# DW_ahb_dmac: IP-XACT component
VLNV Synopsys:DesignWareLibrary:DW_ahb_dmac:2.14a

## Parameters
USE_FOUNDATION = 1 — USE_FOUNDATION. The component code utilizes DesignWare Foundation parts for optimal Synthesis QoR. Customers with only a DesignWare license MUST use Foundation parts. Customers with only a Source license, CANNOT use Foundation parts. Customers with both Source and DesignWare licenses have the option of using Foundation parts.
DMAH_NUM_MASTER_INT = 1 — DMAH_NUM_MASTER_INT. Number of AHB master interfaces. A channel's source and destination device can be programmed to be on any of the configured AHB layer's attached to the AHB Master interfaces. This setting determines if a master interface's signal set is present on the I/O or not. AHB master 1 interface signals are always present.
DMAH_NUM_CHANNELS = 1 — DMAH_NUM_CHANNELS. Number Of DMA channels. Each channel is uni-directional and transfers data from the channel's source to the channel's destination. The channel's source and destination AHB layer, system address and handshaking interface are under software control.
DMAH_NUM_HS_INT = 2 — DMAH_NUM_HS_INT. Number of handshaking interfaces. Each channel's source and destination can be assigned a handshaking interface. This is under software control. If 0 is selected then no hardware handshaking interface signals will be present on the I/O.
DMAH_ID_NUM = 0x0 — DMAH_ID_NUM. This 32-bit value is hardwired and read back by a read to the DMA Controller ID Register (DmaldReg).
DMAH_INTR_POL = 0 — DMAH_INTR_POL. Interrupt active polarity for all of the configured interrupt ports. When this box is selected the interrupt polarity for all interrupt pins on the I/O interface is active low. When this box is de-selected the interrupt polarity for all interrupt pins on the I/O interface is active high.
DMAH_INTR_IO = 2 — DMAH_INTR_IO. Selects which interrupt related pins appear as outputs of the design. all - Contents of all five Interrupts Status Registers appear as output pins on int(_n) output bus. 5 * DMAH_NUM_CHANNELS bits wide. type - All internal interrupts are combined by type and appear on int_flag(_n) output bus. 5 bit bus. bit[4] = Error interrupt bit[3] = Destination transaction complete interrupt bit[2] = Source transaction complete interrupt bit[1] = Block complete interrupt bit[0] = Transfer complete interrupt Bitwise OR of all bits of int_flag(_n) bus is also driven onto the int_combined single bit output port. combined - Bitwise OR of all bits of int_flag(_n) bus is driven onto the int_combined(_n) single bit output port.
DMAH_MABRST = 0 — DMAH_MABRST. Selecting this box will allow software to limit the maximum AMBA burst length to a value under software control. This is a global parameter for all of the configured master interfaces. If this box is not selected then software cannot limit the the maximum AMBA burst length. The maximum possible AMBA burst length in this case will be determined by the depth of the channel FIFO's as the DMA controller may try to fill/empty the channel FIFO in a single AMBA burst. De-selecting this box will allow for some logic optimization.
DMAH_INCR_BURSTS = 1 — DMAH_INCR_BURSTS. When this option is selected then all bursts will be undefined length bursts. When this option is not selected then all bursts will be defined length bursts.
DMAH_RETURN_ERR_RESP = 1 — DMAH_RETURN_ERR_RESP. Selecting this box will allow the slave interface to return an error response on the hresp bus when an illegal access is attempted over the AHB slave interface. An illegal access is any of the following: 1. An AMBA transfer of hsize > 64 bits is attempted. 2. hsel is asserted but the address does not decode to a valid address. 3. A write to the sar, dar, ctl, llp, sstat, dstat, sstatar and dstatar registers is attempted when the channel is enabled. 4. A read from the interrupt clear registers, ClearTfr, ClearBlock, ClearSrcTran, ClearDstTran, ClearErr is attempted. 5. A write to the Interrupt status registers, StatusTfr, StatusBlock, StatusSrcTran, StatusDstTran, StatusErr is attempted. 6. A write to the StatusInt register is attempted. 7. A write to either the DmaIdReg or DmaVersionId registers is attempted. De-selecting this box will result in an O.K. response been returned on the hresp bus for all off the illegal access's listed above. Note in both cases an illegal read will read back 0 and an illegal write will be ignored.
DMAH_ADD_ENCODED_PARAMS = 0x1 — Adding the encoded parameters gives firmware an easy and quick way of identifying the DesignWare component within an I/O memory map. Some critical design-time options determine how a driver should interact with the peripheral. There is a minimal area overhead when you include these parameters. Additionally, this option allows a self-configurable single driver to be developed for each component.
DMAH_STATIC_ENDIAN_SELECT = 1 — DMAH_STATIC_ENDIAN_SELECT. The endianness of the DW_ahb_dmac can be configured statically through coreConsultant or dynamically via pins on the I/O - For the static case there is a single coreConsultant parameter that controls the endianness of all AHB master interfaces and the AHB slave interface. For the dynamic case there is an individual pin for each of the AHB master interfaces and one for the AHB slave interface.
DMAH_BIG_ENDIAN = 0 — DMAH_BIG_ENDIAN. The AHB master interfaces and the AHB slave interface can be configured to exist in either a big or little endian system. All master interfaces and the AHB slave interface have the same endianness. If this box is selected then all configured AHB master interfaces and the AHB slave interface will be configured to be big endian. If this box is de-selected then all configured AHB master interfaces and the AHB slave interface will be configured to be little endian.
DMAH_S_HDATA_WIDTH = 32 — DMAH_S_HDATA_WIDTH. Slave interface data bus width.
DMAH_M{n}_AHB_LITE = 0 (n=1..4) — DMAH_M{n}_AHB_LITE. Select this box if master interface {n} is the only master on this AMBA layer. If this is the case then this is an AMBA-Lite layer. De-select this box if there is more than one master on this AMBA layer.
DMAH_M{n}_HDATA_WIDTH = 32 (n=1..4) — DMAH_M{n}_HDATA_WIDTH. Master {n} interface data bus width.
DMAH_CH{n}_FIFO_DEPTH = 16 (n=0..7) — DMAH_CH{n}_FIFO_DEPTH. Channel {n} FIFO depth in bytes.
DMAH_CH{n}_MAX_MULT_SIZE = 8 (n=0..7) — DMAH_CH{n}_MAX_MULT_SIZE. Maximum value of burst transaction size that can be programmed for channel {n}. Programming either of the ctl{n}.src_msize or ctl{n}.dest_msize registers to a value greater than this cC constant will result in erroneous behavior. Limiting this value with a cC constant will allow for some logic optimization of the implementation.
DMAH_CH{n}_MAX_BLK_SIZE = 31 (n=0..7) — DMAH_CH{n}_MAX_BLK_SIZE. The behavior of this cC constant is dependent on the assignment of the flow control peripheral. 1. DMA is flow controller Maximum block length, in multiples off source transfer width, that can be programmed for channel {n}. A programmed value greater than this will result in erroneous behavior. 2. Either of the source or destination peripherals assigned as flow controller In this case the blocks can be greater than DMAH_CH{n}_MAX_BLK_SIZE but the logic that keeps track of the length of the block saturates at DMAH_CH{n}_MAX_BLK_SIZE. This will not result in erroneous behavior but a readback of the block size will be incorrect when blocks exceed the saturated value. This parameter is also used to limit channel {n}'s scatter and gather count registers to hold a maximum value of DMAH_CH{n}_MAX_BLK_SIZE. Limiting this value with a cC constant will allow for some logic optimization of the implementation.
DMAH_CH{n}_FC = 0 (n=0..7) — DMAH_CH{n}_FC. Hardcode the flow control peripheral for channel {n}. Hardcoding the flow control peripheral will allow for some logic optimization of the implementation. DMA_FC : Hardcodes the DMA as the block flow controlling device SRC_FC_ONLY : Hardcodes the source peripheral as the block flow controlling device DST_FC_ONLY : Hardcodes the destination peripheral as the block flow controlling device ANY_FC : Does not hardcode the block flow control device and allows software to select the block flow control device.
DMAH_CH{n}_LOCK_EN = 0 (n=0..7) — DMAH_CH{n}_LOCK_EN. Include or exclude logic to enable channel or bus level locking on channel {n}. When enabled, then software can program the DMA controller to assert hlock over the DMA transfer, DMA block transfer or DMA transaction. When enabled, then software can also program the DMA controller to lock the arbitration for the master bus interface unit over the DMA transfer, DMA block transfer or DMA transaction. De-selecting this option allows for some logic optimization of the implementation.
DMAH_CH{n}_SMS = 0 (n=0..7) — DMAH_CH{n}_SMS. Hardcode the Master interface attached to the source of channel {n}. If this is not hardcoded then software can program the source of channel {n} to be attached to any of the configured layers. Hardcoding this value will allow for some logic optimization of the implementation.
DMAH_CH{n}_DMS = 0 (n=0..7) — DMAH_CH{n}_DMS. Hardcode the Master interface attached to the destination of channel {n}. If this is not hardcoded then software can program the destination of channel {n} to be attached to any of the configured layers. Hardcoding this value will allow for some logic optimization of the implementation.
DMAH_CH{n}_STW = 32 (n=0..7) — DMAH_CH{n}_STW. Hardcode the source transfer width for transfers from the source of channel {n}. If this is not hardcoded then software can program the source transfer width for channel {n}. Hardcoding this value will allow for some logic optimization of the implementation.
DMAH_CH{n}_DTW = 32 (n=0..7) — DMAH_CH{n}_DTW. Hardcode the destination transfer width for transfers from the destination of channel {n}. If this is not hardcoded then software can program the destination transfer width for channel {n}. Hardcoding this value will allow for some logic optimization of the implementation.
DMAH_CH0_SRC_NON_OK = 1 — DMAH_CH0_SRC_NON_OK. Should be selected if the source peripheral attached to channel 0 can return a non-ok response on hresp. i.e. either split, retry or error response. If this box is de-selected then hardware assumes that only o.k. responses will be returned from the source of channel 0. De-selecting this box will allow for some logic optimization of the implementation.
DMAH_CH0_DST_NON_OK = 1 — DMAH_CH0_DST_NON_OK. Should be selected if the destination peripheral attached to channel 0 can return a non-ok response on hresp. i.e. either split, retry or error response. If this box is de-selected then hardware assumes that only o.k. responses will be returned from the destination of channel 0. De-selecting this box will allow for some logic optimization of the implementation.
DMAH_CH{n}_MULTI_BLK_EN = 0 (n=0..7) — DMAH_CH{n}_MULTI_BLK_EN. Include or exclude logic to enable multi-block DMA transfers on channel {n}. If this option is de-selected then hardware will hardwire channel {n} to do single block transfers only. De-selecting this box will allow for some logic optimization of the implementation.
DMAH_CH{n}_HC_LLP = 1 (n=0..7) — DMAH_CH{n}_HC_LLP. If the Linked List Pointer ( LLP ) register is hardcoded to 0 then this will disable the following features on channel {n}: 1. Multi-block DMA transfers using block chaining 2. Source and destination status fetch 3. Control and source/destination status writeback Multi-block DMA transfers may still be enabled on channel {n} through auto-reloading of channel registers. Selecting this box will allow for some logic optimization of the implementation.
DMAH_CH{n}_MULTI_BLK_TYPE = 0 (n=0..7) — DMAH_CH{n}_MULTI_BLK_TYPE. This parameter allows the user to hardcode the type of multi-block transfers that the DW_ahb_dmac can perform. This will result in some logic optimization of the implementation. NO_HARDCODE : Allow all types of multi-block support CONT_RELOAD : Allow only multi-block transfers where SAR{n} is contigious, DAR{n} and CTL{n} are reloaded from their initial values RELOAD_CONT : Allow only multi-block transfers where SAR{n} and CTL{n} are reloaded from their initial values, DAR{n} is contigious RELOAD_RELOAD : Allow only multi-block transfers where SAR{n},DAR{n} and CTL{n} are reloaded from their initial values CONT_LLP : Allow only multi-block transfers where SAR{n} is contigious, DAR{n},CTL{n} and LLP{n} are loaded from the next Linked List Item RELOAD_LLP : Allow only multi-block transfers where SAR{n} is reloaded from it's initial value, DAR{n},CTL{n} and LLP{n} are loaded from the next Linked List Item LLP_CONT : Allow only multi-block transfers where SAR{n},CTL{n} and LLP{n} are loaded from the next Linked List Item, DAR{n} is contigious LLP_RELOAD : Allow only multi-block transfers where SAR{n},CTL{n} and LLP{n} are loaded from the next Linked List Item, DAR{n} is reloaded from it's initial values LLP_LLP : Allow only multi-block transfers where SAR{n},DAR{n},CTL{n} and LLP{n} are loaded from the next
DMAH_CH{n}_STAT_SRC = 0 (n=0..7) — DMAH_CH{n}_STAT_SRC. Include or exclude logic to fetch a status register from the source peripheral of channel {n} and write this status information to system memory at the end of each block transfer. The location from where the source status register is fetched from is under software control as is the writeback location. De-selecting this box will allow for some logic optimization of the implementation.
DMAH_CH{n}_STAT_DST = 0 (n=0..3) — DMAH_CH{n}_STAT_DST. Include or exclude logic to fetch a status register from the destination peripheral of channel {n} and write this status information to system memory at the end of each block transfer. The location from where the destination status register is fetched from is under software control as is the writeback location. De-selecting this box will allow for some logic optimization of the implementation.
DMAH_CH{n}_LMS = 0 (n=0..7) — DMAH_CH{n}_LMS. Hardcode the Master interface attached to the Linked List Pointer (LLP) peripheral of channel {n}. If this is not hardcoded then software can program the LLP peripheral of channel {n} to be attached to any of the configured layers. Hardcoding this value will allow for some logic optimization of the implementation.
DMAH_CH0_LLP_NON_OK = 0 — DMAH_CH0_LLP_NON_OK. Should be selected if the linked list pointer (LLP) peripheral attached to channel 0 can return a non-ok response on hresp. i.e. either split, retry or error response. If de-selected then hardware assumes that only o.k. responses will be returned from the LLP peripheral of channel 0. De-selecting this box will allow for some logic optimization of the implementation.
DMAH_CH{n}_SRC_GAT_EN = 0 (n=0..7) — DMAH_CH{n}_SRC_GAT_EN. Include or exclude logic to enable the 'gather' feature on channel {n}. De-selecting this box will allow for some logic optimization of the implementation.
DMAH_CH{n}_DST_SCA_EN = 0 (n=0..7) — DMAH_CH{n}_DST_SCA_EN. Include or exclude logic to enable the 'scatter' feature on channel {n}. De-selecting this box will allow for some logic optimization of the implementation.
DMAH_CH{n}_CTL_WB_EN = 0 (n=0..7) — DMAH_CH{n}_CTL_WB_EN. Include or exclude logic to enable writeback of the control register at the end of every block transfer. De-selecting this box will allow for some logic optimization of the implementation.
DMAH_CH{n}_SRC_NON_OK = 1 (n=1..7) — DMAH_CH{n}_SRC_NON_OK. Should be selected if the source peripheral attached to channel {n} can return a non-ok response on hresp. i.e. either split/retry or error response. If this box is de-selected then hardware assumes that only o.k. responses will be returned from the source of channel {n}. De-selecting this box will allow for some logic optimization of the implementation.
DMAH_CH{n}_DST_NON_OK = 1 (n=1..7) — DMAH_CH{n}_DST_NON_OK. Should be selected if the destination peripheral attached to channel {n} can return a non-ok response on hresp. i.e. either split/retry or error response. If this box is de-selected then hardware assumes that only o.k. responses will be returned from the destination of channel {n}. De-selecting this box will allow for some logic optimization of the implementation.
DMAH_CH1_LLP_NON_OK = 0 — DMAH_CH1_LLP_NON_OK. Should be selected to true if the linked list pointer (LLP) peripheral attached to channel 1 can return a non-ok response on hresp. i.e. either split, retry or error response. If de-selected then hardware assumes that only o.k. responses will be returned from the LLP peripheral of channel 1. De-selecting this box will allow for some logic optimization of the implementation.
DMAH_CH2_LLP_NON_OK = 0 — DMAH_CH2_LLP_NON_OK. Should be selected to true if the linked list pointer (LLP) peripheral attached to channel 2 can return a non-ok response on hresp. i.e. either split, retry or error response. If de-selected then hardware assumes that only o.k. responses will be returned from the LLP peripheral of channel 2. De-selecting this box will allow for some logic optimization of the implementation.
DMAH_CH3_LLP_NON_OK = 0 — DMAH_CH3_LLP_NON_OK. Should be set to true if the linked list pointer (LLP) peripheral attached to channel 3 can return a non-ok response on hresp. i.e. either split, retry or error response. If de-selected then hardware assumes that only o.k. responses will be returned from the LLP peripheral of channel 3. De-selecting this box will allow for some logic optimization of the implementation.
DMAH_CH4_STAT_DST = 0 — DMAH_CH4_STAT_DST. Include or exclude logic to fetch a status register from the destination peripheral of channel 0 and write this status information to system memory at the end of each block transfer. The location from where the destination status register is fetched from is under software control as is the writeback location. De-selecting this box will allow for some logic optimization of the implementation.
DMAH_CH{n}_LLP_NON_OK = 0 (n=4..7) — DMAH_CH{n}_LLP_NON_OK. Should be selected to true if the linked list pointer (LLP) peripheral attached to channel {n} can return a non-ok response on hresp. i.e. either split, retry or error response. If de-selected then hardware assumes that only o.k. responses will be returned from the LLP peripheral of channel {n}. De-selecting this box will allow for some logic optimization of the implementation.
DMAH_CH{n}_STAT_DST = 0 (n=5..7) — DMAH_CH{n}_STAT_DST. Include or exclude logic to fetch a status register from the destination peripheral of channel {n} and write this status information to system memory at the end of each block transfer. The location from where the destination status register is fetched from is under software control as is the writeback location. De-selecting this box will allow for some logic optimization of the implementation.

## Bus interfaces (logical=physical port)
AHB_Master1: master amba.com:busdef.amba.amba2:ahb:r1p0 — Bus Master side of the AHB. On this interface the 'consumer's are AHB masters, and the 'provider' is the central bus IP.
  hsize=hsize1, hresp=hresp1, hgrant=hgrant1, hburst=hburst1, hwrite=hwrite1, hwdata=hwdata1, htrans=htrans1, hbusreq=hbusreq1, hrdata=hrdata1, hready=hready1, haddr=haddr1, hprot=hprot1, hlock=hlock1
AHB_Slave: slave amba.com:busdef.amba.amba2:ahb:r1p0 — Bus Slave side of the AHB. On this interface the 'consumer's are AHB slaves, and the 'provider' is the central bus IP.
  hsel=hsel, hready_resp=hready_resp, hrdata=hrdata, htrans=htrans, hsize=hsize, hready=hready, hwrite=hwrite, haddr=haddr, hresp=hresp, hwdata=hwdata
HCLK: system amba.com:busdef.amba.amba2:ahb:r1p0 — Clock signal for AHB masters and slaves. Connections typically go from an exported interface to each AHB master/slave and the bus itself.
  hclk=hclk
HRESETn: system amba.com:busdef.amba.amba2:ahb:r1p0 — Reset signal for AHB masters and slaves. Connections typically go from an exported interface to each AHB master/slave and the bus itself.
  hresetn=hresetn
int_combined: mirroredSlave Synopsys:DesignWareLibrary:DW-SoC::Source-Interrupt:2.0 — Source interrupt signals connected to an interrupt controller.
  irq=int_combined_n

## Ports
in dma_last[1:0]
in dma_req[1:0]
in dma_single[1:0]
in haddr[31:0]
in hclk
in hgrant1
in hrdata1[31:0]
in hready
in hready1
in hresetn
in hresp1[1:0]
in hsel
in hsize[2:0]
in htrans[1:0]
in hwdata[31:0]
in hwrite
out debug_ch_enable[0:0]
out debug_dma_ctl_en
out debug_dma_data_req[1:0]
out debug_dum_req_dst_region[0:0]
out debug_dum_req_src_region[0:0]
out debug_en_dst_hs_sgl[0:0]
out debug_en_src_hs_sgl[0:0]
out debug_fifo_empty[0:0]
out debug_fifo_half_full[0:0]
out debug_fifo_ready_dst[0:0]
out debug_fifo_ready_src[0:0]
out debug_grant_index_m1[0:0]
out debug_granted_m1
out debug_length_m_i[4:0]
out debug_mask_lck_ch_m1[1:0]
out debug_rd_int_en[0:0]
out debug_rd_maskblock[0:0]
out debug_rd_maskdsttran[0:0]
out debug_rd_maskerr[0:0]
out debug_rd_masksrctran[0:0]
out debug_rd_masktfr[0:0]
out debug_rd_rawblock[0:0]
out debug_rd_rawdsttran[0:0]
out debug_rd_rawerr[0:0]
out debug_rd_rawsrctran[0:0]
out debug_rd_rawtfr[0:0]
out debug_req_mi1[1:0]
out debug_statusint_dmacore[4:0]
out debug_tfr_req_m1
out dma_ack[1:0]
out dma_finish[1:0]
out haddr1[31:0]
out hburst1[2:0]
out hbusreq1
out hlock1
out hprot1[3:0]
out hrdata[31:0]
out hready_resp
out hresp[1:0]
out hsize1[2:0]
out htrans1[1:0]
out hwdata1[31:0]
out hwrite1
out int_combined_n

## Address spaces and blocks
DMAC.Software_Handshake_Registers: base 0x368, range 0x30, width 64, register
DMAC.Miscellaneous_Registers: base 0x398, range 0x68, width 64, register
DMAC.Interrupt_Registers: base 0x2c0, range 0xa8, width 64, register
DMAC.Channel_0_Registers: base 0x0, range 0x58, width 64, register

## Registers
Registers are 64-bit, read-write, reset 0x0 unless marked. A register's access mark holds for its fields unless they carry their own. Offsets are from the block's base; lines under a group give offsets from that group; [hi:lo] are bit positions; {n}, {i} and the like mark numbered series; 'fields as' and 'values as' point back to an identical list; <NAME> marks a mode.

## DMAC.Software_Handshake_Registers
Base 0x00000368
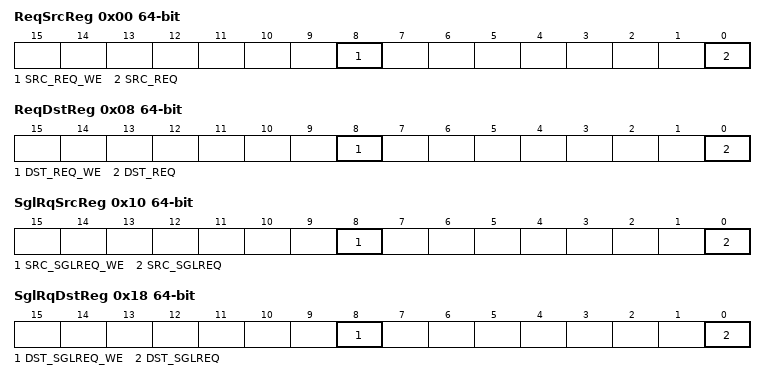
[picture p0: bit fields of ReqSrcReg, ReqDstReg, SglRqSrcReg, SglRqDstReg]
0x00 ReqSrcReg
  [8] SRC_REQ_WE, [0] SRC_REQ
0x08 ReqDstReg
  [8] DST_REQ_WE, [0] DST_REQ
0x10 SglRqSrcReg
  [8] SRC_SGLREQ_WE, [0] SRC_SGLREQ
0x18 SglRqDstReg
  [8] DST_SGLREQ_WE, [0] DST_SGLREQ
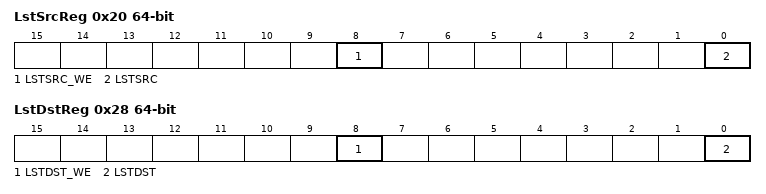
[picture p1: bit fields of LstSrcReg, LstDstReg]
0x20 LstSrcReg
  [8] LSTSRC_WE, [0] LSTSRC
0x28 LstDstReg
  [8] LSTDST_WE, [0] LSTDST

## DMAC.Miscellaneous_Registers
Base 0x00000398
0x00 DmaCfgReg reset not defined
  [0] DMA_EN
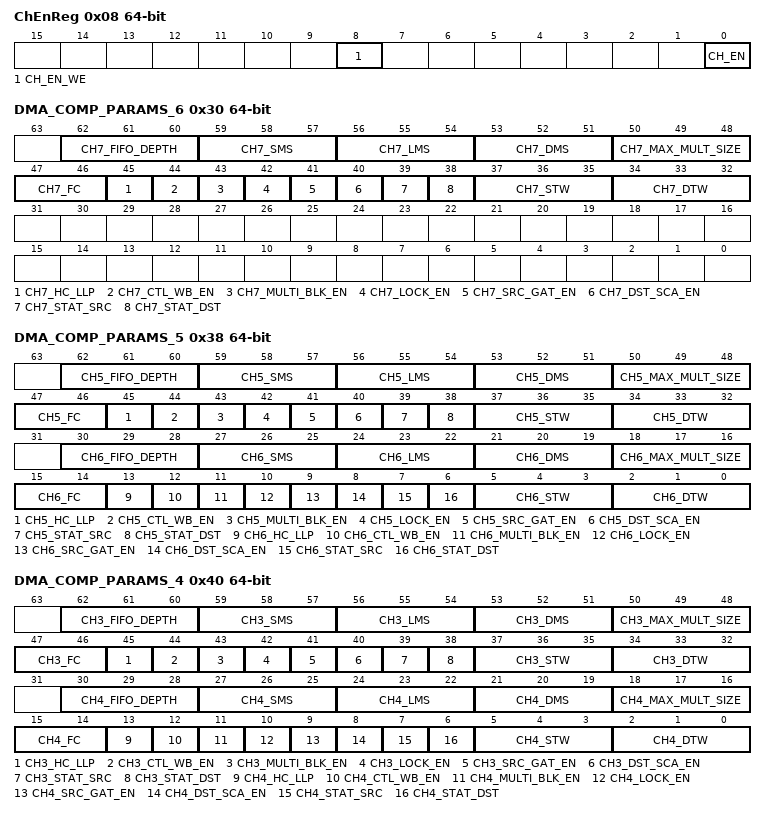
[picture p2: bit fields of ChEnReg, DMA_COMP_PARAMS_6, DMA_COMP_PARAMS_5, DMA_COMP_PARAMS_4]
0x08 ChEnReg reset not defined
  [8] CH_EN_WE, [0] CH_EN
0x10 DmaIdReg ro
  [31:0] DMA_ID
0x18 DmaTestReg reset not defined
  [0] TEST_SLV_IF
0x30 DMA_COMP_PARAMS_6 ro reset not defined
  [62:60] CH7_FIFO_DEPTH, [59:57] CH7_SMS, [56:54] CH7_LMS, [53:51] CH7_DMS, [50:48] CH7_MAX_MULT_SIZE, [47:46] CH7_FC, [45] CH7_HC_LLP, [44] CH7_CTL_WB_EN, [43] CH7_MULTI_BLK_EN, [42] CH7_LOCK_EN, [41] CH7_SRC_GAT_EN, [40] CH7_DST_SCA_EN, [39] CH7_STAT_SRC, [38] CH7_STAT_DST, [37:35] CH7_STW, [34:32] CH7_DTW
0x38 DMA_COMP_PARAMS_5 ro reset not defined
  [62:60] CH5_FIFO_DEPTH, [59:57] CH5_SMS, [56:54] CH5_LMS, [53:51] CH5_DMS, [50:48] CH5_MAX_MULT_SIZE, [47:46] CH5_FC, [45] CH5_HC_LLP, [44] CH5_CTL_WB_EN, [43] CH5_MULTI_BLK_EN, [42] CH5_LOCK_EN, [41] CH5_SRC_GAT_EN, [40] CH5_DST_SCA_EN, [39] CH5_STAT_SRC, [38] CH5_STAT_DST, [37:35] CH5_STW, [34:32] CH5_DTW, [30:28] CH6_FIFO_DEPTH, [27:25] CH6_SMS, [24:22] CH6_LMS, [21:19] CH6_DMS, [18:16] CH6_MAX_MULT_SIZE, [15:14] CH6_FC, [13] CH6_HC_LLP, [12] CH6_CTL_WB_EN, [11] CH6_MULTI_BLK_EN, [10] CH6_LOCK_EN, [9] CH6_SRC_GAT_EN, [8] CH6_DST_SCA_EN, [7] CH6_STAT_SRC, [6] CH6_STAT_DST, [5:3] CH6_STW, [2:0] CH6_DTW
0x40 DMA_COMP_PARAMS_4 ro reset not defined
  [62:60] CH3_FIFO_DEPTH, [59:57] CH3_SMS, [56:54] CH3_LMS, [53:51] CH3_DMS, [50:48] CH3_MAX_MULT_SIZE, [47:46] CH3_FC, [45] CH3_HC_LLP, [44] CH3_CTL_WB_EN, [43] CH3_MULTI_BLK_EN, [42] CH3_LOCK_EN, [41] CH3_SRC_GAT_EN, [40] CH3_DST_SCA_EN, [39] CH3_STAT_SRC, [38] CH3_STAT_DST, [37:35] CH3_STW, [34:32] CH3_DTW, [30:28] CH4_FIFO_DEPTH, [27:25] CH4_SMS, [24:22] CH4_LMS, [21:19] CH4_DMS, [18:16] CH4_MAX_MULT_SIZE, [15:14] CH4_FC, [13] CH4_HC_LLP, [12] CH4_CTL_WB_EN, [11] CH4_MULTI_BLK_EN, [10] CH4_LOCK_EN, [9] CH4_SRC_GAT_EN, [8] CH4_DST_SCA_EN, [7] CH4_STAT_SRC, [6] CH4_STAT_DST, [5:3] CH4_STW, [2:0] CH4_DTW
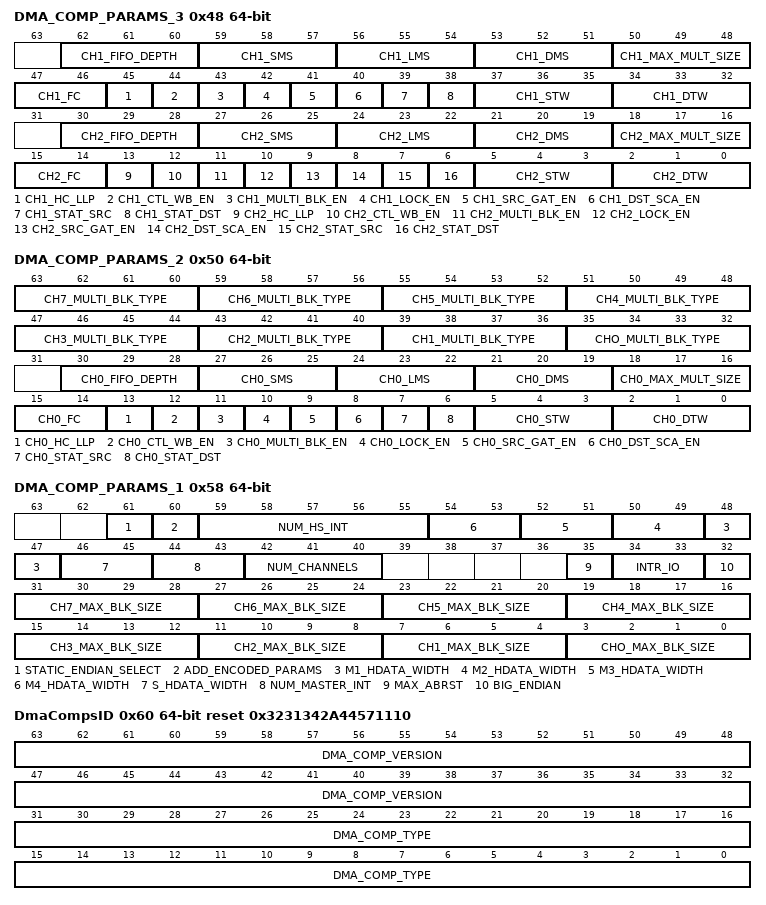
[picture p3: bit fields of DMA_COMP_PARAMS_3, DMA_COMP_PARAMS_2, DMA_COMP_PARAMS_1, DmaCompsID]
0x48 DMA_COMP_PARAMS_3 ro reset not defined
  [62:60] CH1_FIFO_DEPTH, [59:57] CH1_SMS, [56:54] CH1_LMS, [53:51] CH1_DMS, [50:48] CH1_MAX_MULT_SIZE, [47:46] CH1_FC, [45] CH1_HC_LLP, [44] CH1_CTL_WB_EN, [43] CH1_MULTI_BLK_EN, [42] CH1_LOCK_EN, [41] CH1_SRC_GAT_EN, [40] CH1_DST_SCA_EN, [39] CH1_STAT_SRC, [38] CH1_STAT_DST, [37:35] CH1_STW, [34:32] CH1_DTW, [30:28] CH2_FIFO_DEPTH, [27:25] CH2_SMS, [24:22] CH2_LMS, [21:19] CH2_DMS, [18:16] CH2_MAX_MULT_SIZE, [15:14] CH2_FC, [13] CH2_HC_LLP, [12] CH2_CTL_WB_EN, [11] CH2_MULTI_BLK_EN, [10] CH2_LOCK_EN, [9] CH2_SRC_GAT_EN, [8] CH2_DST_SCA_EN, [7] CH2_STAT_SRC, [6] CH2_STAT_DST, [5:3] CH2_STW, [2:0] CH2_DTW
0x50 DMA_COMP_PARAMS_2 ro reset not defined
  [4n+35:4n+32] CH{n}_MULTI_BLK_TYPE (n=1..7), [35:32] CHO_MULTI_BLK_TYPE, [30:28] CH0_FIFO_DEPTH, [27:25] CH0_SMS, [24:22] CH0_LMS, [21:19] CH0_DMS, [18:16] CH0_MAX_MULT_SIZE, [15:14] CH0_FC, [13] CH0_HC_LLP, [12] CH0_CTL_WB_EN, [11] CH0_MULTI_BLK_EN, [10] CH0_LOCK_EN, [9] CH0_SRC_GAT_EN, [8] CH0_DST_SCA_EN, [7] CH0_STAT_SRC, [6] CH0_STAT_DST, [5:3] CH0_STW, [2:0] CH0_DTW
0x58 DMA_COMP_PARAMS_1 ro reset not defined
  [61] STATIC_ENDIAN_SELECT, [60] ADD_ENCODED_PARAMS, [59:55] NUM_HS_INT, [2n+46:2n+45] M{n}_HDATA_WIDTH (n=1..4), [46:45] S_HDATA_WIDTH, [44:43] NUM_MASTER_INT, [42:40] NUM_CHANNELS, [35] MAX_ABRST, [34:33] INTR_IO, [32] BIG_ENDIAN, [4n+3:4n] CH{n}_MAX_BLK_SIZE (n=1..7), [3:0] CHO_MAX_BLK_SIZE
0x60 DmaCompsID ro reset 0x3231342A44571110
  [63:32] DMA_COMP_VERSION, [31:0] DMA_COMP_TYPE

## DMAC.Interrupt_Registers
Base 0x000002C0
0x00 RawTfr
  [0] RAW
0x08 RawBlock
  [0] RAW
0x10 RawSrcTran
  [0] RAW
0x18 RawDstTran
  [0] RAW
0x20 RawErr
  [0] RAW
0x28 StatusTfr ro
  [0] RAW
0x30 StatusBlock ro
  [0] RAW
0x38 StatusSrcTran ro
  [0] RAW
0x40 StatusDstTran ro
  [0] RAW
0x48 StatusErr ro
  [0] RAW
0x50 MaskTfr
  [0] RAW
0x58 MaskBlock
  [0] RAW
0x60 MaskSrcTran
  [0] RAW
0x68 MaskDstTran
  [0] RAW
0x70 MaskErr
  [0] RAW
0x78 ClearTfr wo reset not defined
  [0] RAW
0x80 ClearBlock wo reset not defined
  [0] RAW
0x88 ClearSrcTran wo reset not defined
  [0] RAW
0x90 ClearDstTran wo reset not defined
  [0] RAW
0x98 ClearErr wo reset not defined
  [0] RAW
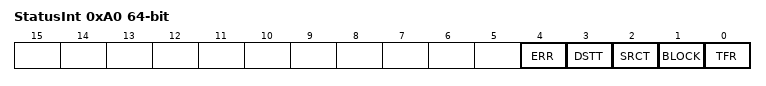
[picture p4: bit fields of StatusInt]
0xA0 StatusInt
  [4] ERR, [3] DSTT, [2] SRCT, [1] BLOCK, [0] TFR

## DMAC.Channel_0_Registers
Base 0x00000000
0x00 SAR0
  [31:0] SAR
0x08 DAR0
  [31:0] DAR
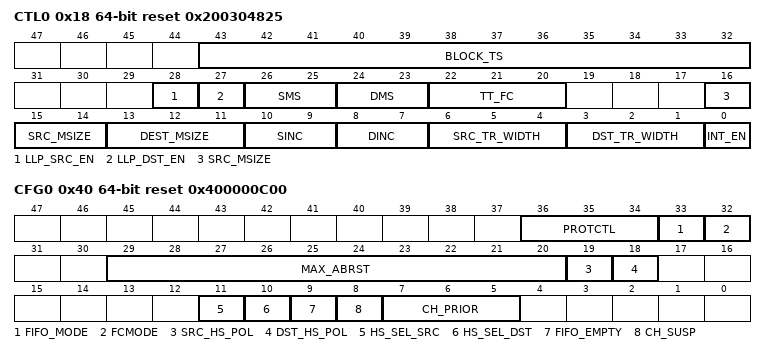
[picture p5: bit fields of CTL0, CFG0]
0x18 CTL0 reset 0x200304825
  [43:32] BLOCK_TS, [28] LLP_SRC_EN, [27] LLP_DST_EN, [26:25] SMS, [24:23] DMS, [22:20] TT_FC, [16:14] SRC_MSIZE, [13:11] DEST_MSIZE, [10:9] SINC, [8:7] DINC, [6:4] SRC_TR_WIDTH, [3:1] DST_TR_WIDTH, [0] INT_EN
0x40 CFG0 reset 0x400000C00
  [36:34] PROTCTL, [33] FIFO_MODE, [32] FCMODE, [29:20] MAX_ABRST, [19] SRC_HS_POL, [18] DST_HS_POL, [11] HS_SEL_SRC, [10] HS_SEL_DST, [9] FIFO_EMPTY, [8] CH_SUSP, [7:5] CH_PRIOR
